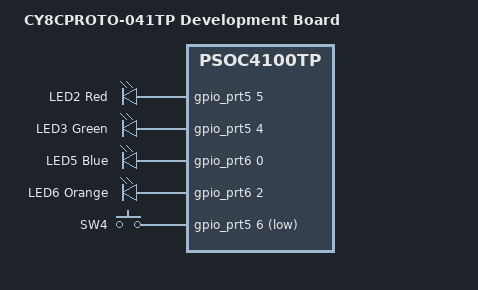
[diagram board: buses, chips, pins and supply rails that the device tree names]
/*
 * Copyright (c) 2025 Infineon Technologies AG,
 * or an affiliate of Infineon Technologies AG.
 *
 * SPDX-License-Identifier: Apache-2.0
 */

/dts-v1/;
#include <arm/infineon/psoc4/mpns/cy8c4147azq_t495.dtsi>
#include <arm/infineon/psoc4/psoc4100tp/system_clocks.dtsi>

#include "cy8cproto_041tp_common.dtsi"

/ {
	model = "CY8CPROTO-041TP Development Board";
	compatible = "infineon,cy8cproto-041tp", "infineon,psoc4100tp";

	chosen {
		zephyr,sram = &sram0;
		zephyr,flash = &flash0;
		zephyr,console = &uart0;
		zephyr,shell-uart = &uart0;
	};

	aliases {
		led0 = &user_led2;
		led1 = &user_led3;
		led2 = &user_led5;
		led3 = &user_led6;
		sw0 = &user_sw4;
	};

	leds {
		compatible = "gpio-leds";
		status = "okay";

		user_led2: red_led: led_0 {
			label = "LED2 Red";
			gpios = <&gpio_prt5 5 GPIO_ACTIVE_HIGH>;
		};

		user_led3: green_led: led_1 {
			label = "LED3 Green";
			gpios = <&gpio_prt5 4 GPIO_ACTIVE_HIGH>;
		};

		user_led5: blue_led: led_2 {
			label = "LED5 Blue";
			gpios = <&gpio_prt6 0 GPIO_ACTIVE_HIGH>;
		};

		user_led6: orange_led: led_3 {
			label = "LED6 Orange";
			gpios = <&gpio_prt6 2 GPIO_ACTIVE_HIGH>;
		};
	};

	gpio_keys {
		compatible = "gpio-keys";

		user_sw4: user_btn: button {
			label = "SW4";
			gpios = <&gpio_prt5 6 (GPIO_PULL_UP | GPIO_ACTIVE_LOW)>;
			zephyr,code = <INPUT_KEY_0>;
		};
	};
};
